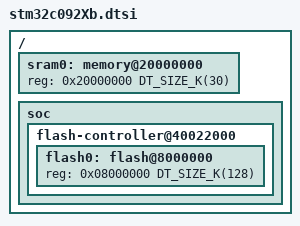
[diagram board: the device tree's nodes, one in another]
/*
 * Copyright (c) 2024 STMicroelectronics
 * Copyright (c) 2025 Thomas Stranger
 *
 * SPDX-License-Identifier: Apache-2.0
 */

#include <st/c0/stm32c092.dtsi>

/ {
	sram0: memory@20000000 {
		reg = <0x20000000 DT_SIZE_K(30)>;
	};

	soc {
		flash-controller@40022000 {
			flash0: flash@8000000 {
				reg = <0x08000000 DT_SIZE_K(128)>;
				ranges = <0x0 0x8000000 DT_SIZE_K(128)>;
				#address-cells = <1>;
				#size-cells = <1>;
			};
		};
	};
};
